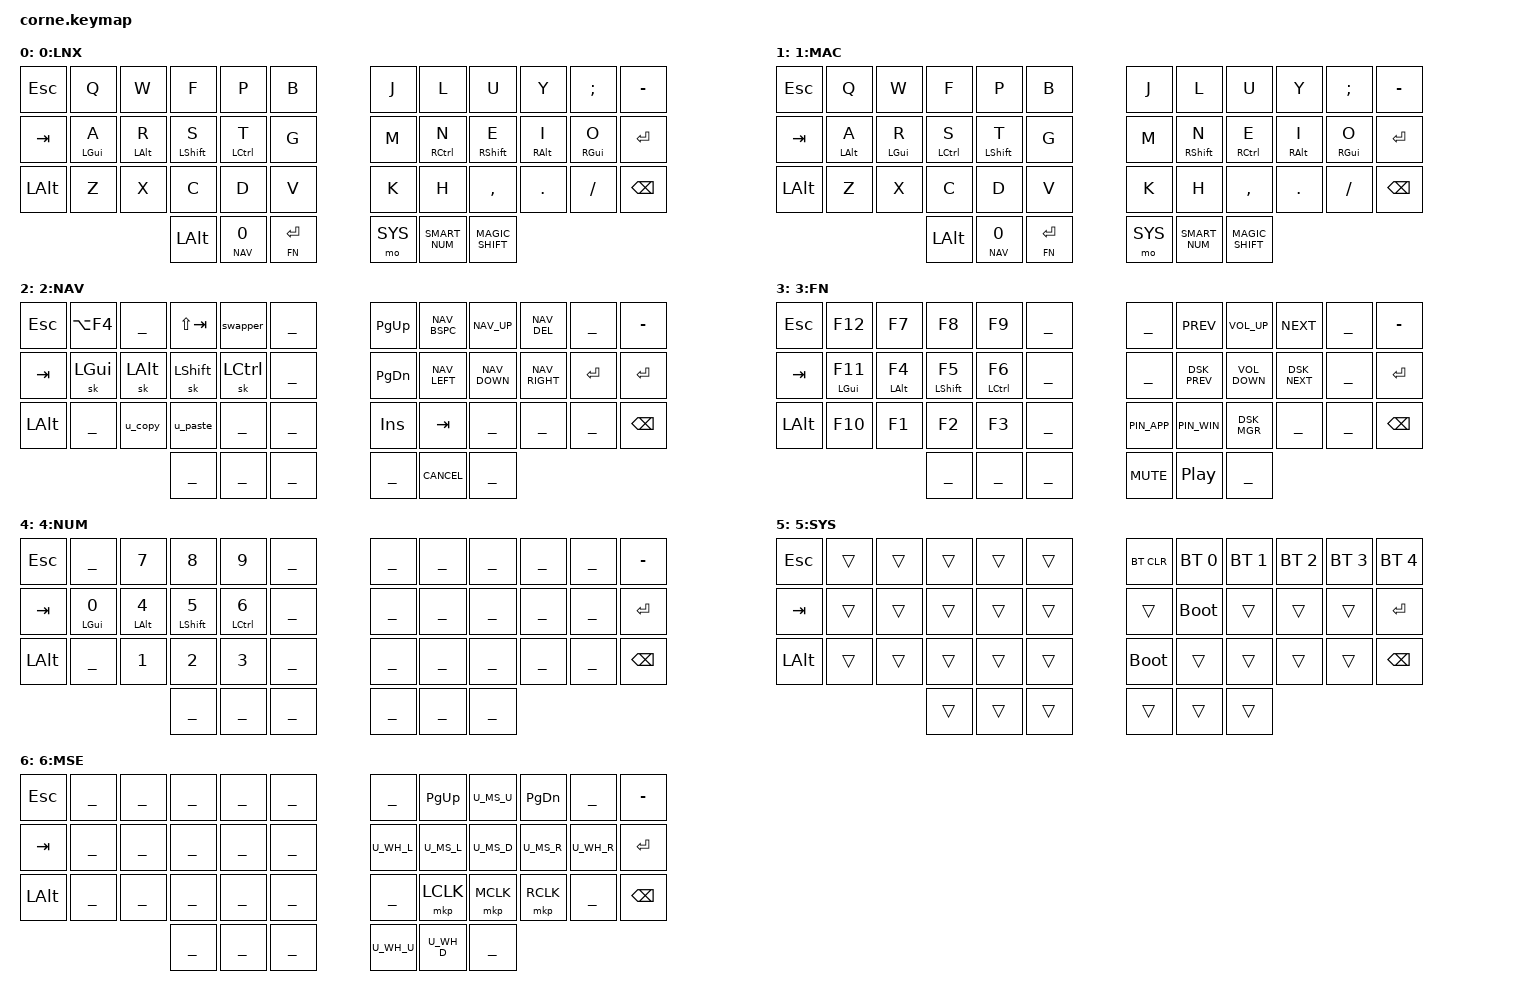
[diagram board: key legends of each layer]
/*
 * Copyright (c) 2020 The ZMK Contributors
 *
 * SPDX-License-Identifier: MIT
 */

#include <behaviors.dtsi>
#include <dt-bindings/zmk/keys.h>
#include <dt-bindings/zmk/bt.h>
#include <dt-bindings/zmk/ext_power.h>
#include <dt-bindings/zmk/outputs.h>

/*
 * Layer indices for Corne
 */
#undef DEF
#undef NAV
#undef FN
#undef NUM
#undef SYS
#undef MOUSE

#define DEF_LNX 0
#define DEF_MAC 1
#define NAV     2
#define FN      3
#define NUM     4
#define SYS     5
#define MOUSE   6

#define DEF DEF_LNX // Override DEF for base.dtsi compatibility

/*
 * Key labels for 42-key Corne
 */
#include "key-labels/42.h"

/*
 * Source the main keymap and helpers
 */
#define CONFIG_WIRELESS
#include "base.dtsi"

/*
 * 42-key Corne layout macro
 */
#undef ZMK_BASE_LAYER
#define ZMK_BASE_LAYER(name, LT, RT, LM, RM, LB, RB, LH, RH) \
    ZMK_LAYER(name, \
        &kp ESC  LT  RT  &kp MINUS \
        &kp TAB  LM  RM  &kp RET \
        &kp LALT LB  RB  &kp BSPC \
              &kp LCTRL LH RH &mo SYS \
    )

/*
 * German Umlaute via vertical combos (US-International layout on OS)
 */
/ {
    combos {
        compatible = "zmk,combos";
        
        // ä: A (LM4) + Z (LB4)
        combo_ae {
            timeout-ms = <50>;
            key-positions = <LM4 LB4>;
            bindings = <&kp RA(Q)>;
            layers = <DEF_LNX DEF_MAC>;
        };
        // ö: O (RM4) + / (RB4)
        combo_oe {
            timeout-ms = <50>;
            key-positions = <RM4 RB4>;
            bindings = <&kp RA(P)>;
            layers = <DEF_LNX DEF_MAC>;
        };
        // ü: U (RT2) + E (RM2)
        combo_ue {
            timeout-ms = <50>;
            key-positions = <RT2 RM2>;
            bindings = <&kp RA(Y)>;
            layers = <DEF_LNX DEF_MAC>;
        };
        // ß: S (LM2) + C (LB2)
        combo_ss {
            timeout-ms = <50>;
            key-positions = <LM2 LB2>;
            bindings = <&kp RA(S)>;
            layers = <DEF_LNX DEF_MAC>;
        };
    };
};

/*
 * OS-aware Unified Macros & Behaviors
 */
/ {
    macros {
        // Universal Copy (Linux): Ctrl+Insert works in terminal AND browser
        copy_lnx: copy_lnx {
            compatible = "zmk,behavior-macro";
            #binding-cells = <0>;
            bindings = <&kp LC(INS)>;
        };
        // Universal Paste (Linux): Shift+Insert works in terminal AND browser
        paste_lnx: paste_lnx {
            compatible = "zmk,behavior-macro";
            #binding-cells = <0>;
            bindings = <&kp LS(INS)>;
        };
    };

    behaviors {
        // Unified Copy Action (Nav layer + C)
        u_copy: u_copy {
            compatible = "zmk,behavior-mod-morph";
            #binding-cells = <0>;
            bindings = <&copy_lnx>, <&kp LG(C)>;
            mods = <(MOD_LGUI)>; // Dummy mapping to separate logic
        };
        // Unified Paste Action (Nav layer + V)
        u_paste: u_paste {
            compatible = "zmk,behavior-mod-morph";
            #binding-cells = <0>;
            bindings = <&paste_lnx>, <&kp LG(V)>;
            mods = <(MOD_LGUI)>;
        };
    };
};

/*
 * Keymap with Mac and Linux layers
 * Aligned HRM strategy: 
 * Middle finger = LCTRL (Universal tool finger for Vim, Zellij, Kill)
 * Index finger = LALT (Linux/Zellij) / LGUI (Mac)
 */
/ {
    keymap {
        compatible = "zmk,keymap";

        // 0: Base Linux (Index finger = Ctrl)
        base_lnx_layer {
            display-name = "0:LNX";
            bindings = <
        &kp ESC   &kp Q       &kp W       &kp F        &kp P        &kp B          &kp J   &kp L        &kp U        &kp Y       &kp SEMI    &kp MINUS
        &kp TAB   &hml LGUI A &hml LALT R &hml LSHFT S &hml LCTRL T &kp G          &kp M   &hmr RCTRL N &hmr RSHFT E &hmr RALT I &hmr RGUI O &kp RET
        &kp LALT  &kp Z       &kp X       &kp C        &kp D        &kp V          &kp K   &kp H        &kp COMMA    &kp DOT     &kp FSLH    &kp BSPC
                                  &kp LALT     &lt_spc NAV 0 &lt FN RET    &mo SYS SMART_NUM MAGIC_SHIFT
            >;
        };

        // 1: Base Mac (Index finger = GUI/Cmd)
        base_mac_layer {
            display-name = "1:MAC";
            bindings = <
        &kp ESC   &kp Q       &kp W       &kp F        &kp P        &kp B          &kp J   &kp L        &kp U        &kp Y       &kp SEMI    &kp MINUS
        &kp TAB   &hml LALT A  &hml LGUI R &hml LCTRL S &hml LSHFT T &kp G          &kp M   &hmr RSHFT N &hmr RCTRL E &hmr RALT I &hmr RGUI O &kp RET
        &kp LALT  &kp Z       &kp X       &kp C        &kp D        &kp V          &kp K   &kp H        &kp COMMA    &kp DOT     &kp FSLH    &kp BSPC
                                  &kp LALT     &lt_spc NAV 0 &lt FN RET    &mo SYS SMART_NUM MAGIC_SHIFT
            >;
        };


        // 2: Nav (Unified Actions)
        nav_layer {
            display-name = "2:NAV";
            bindings = <
&kp ESC   &kp LA(F4)    ___           &kp LS(TAB)   &swapper      ___            &kp PG_UP     NAV_BSPC      NAV_UP        NAV_DEL       ___         &kp MINUS
&kp TAB   &sk LGUI      &sk LALT      &sk LSHFT     &sk LCTRL     ___            &kp PG_DN     NAV_LEFT      NAV_DOWN      NAV_RIGHT     &kp RET     &kp RET
&kp LALT  ___           &u_copy       &u_paste      ___           ___            &kp INS       &kp TAB       ___           ___           ___         &kp BSPC
                                      ___           ___           ___            ___           CANCEL        ___
            >;
        };

        // 3: Fn
        fn_layer {
            display-name = "3:FN";
            bindings = <
&kp ESC   &kp F12       &kp F7        &kp F8        &kp F9        ___            ___           &kp C_PREV    &kp C_VOL_UP  &kp C_NEXT    ___         &kp MINUS
&kp TAB   &hml LGUI F11 &hml LALT F4  &hml LSHFT F5 &hml LCTRL F6 ___            ___           DSK_PREV      VOL_DOWN      DSK_NEXT      ___         &kp RET
&kp LALT  &kp F10       &kp F1        &kp F2        &kp F3        ___            PIN_APP       PIN_WIN       DSK_MGR       ___           ___         &kp BSPC
                                      ___           ___           ___            &kp C_MUTE    &kp C_PP      ___
            >;
        };

        // 4: Num
        num_layer {
            display-name = "4:NUM";
            bindings = <
&kp ESC   ___           &kp N7        &kp N8        &kp N9        ___            ___           ___           ___           ___           ___         &kp MINUS
&kp TAB   &hml LGUI N0  &hml LALT N4  &hml LSHFT N5 &hml LCTRL N6 ___            ___           ___           ___           ___           ___         &kp RET
&kp LALT  ___           &kp N1        &kp N2        &kp N3        ___            ___           ___           ___           ___           ___         &kp BSPC
                                      ___           ___           ___            ___           ___           ___
            >;
        };

        // 5: Sys
        sys_layer {
            display-name = "5:SYS";
            bindings = <
        &kp ESC   &trans        &trans        &trans        &trans        &trans         &bt BT_CLR    &bt BT_SEL 0  &bt BT_SEL 1  &bt BT_SEL 2  &bt BT_SEL 3  &bt BT_SEL 4
        &kp TAB   &trans        &trans        &trans        &trans        &trans         &trans        &bootloader   &trans        &trans        &trans      &kp RET
        &kp LALT  &trans        &trans        &trans        &trans        &trans         &bootloader   &trans        &trans        &trans        &trans      &kp BSPC
                                      &trans        &trans        &trans         &trans        &trans        &trans
            >;
        };


        // 6: Mouse
        mouse_layer {
            display-name = "6:MSE";
            bindings = <
&kp ESC   ___           ___           ___           ___           ___            ___           &kp PG_UP     U_MS_U         &kp PG_DN    ___         &kp MINUS
&kp TAB   ___           ___           ___           ___           ___            U_WH_L        U_MS_L        U_MS_D         U_MS_R       U_WH_R      &kp RET
&kp LALT  ___           ___           ___           ___           ___            ___           &mkp LCLK     &mkp MCLK      &mkp RCLK    ___         &kp BSPC
                                      ___           ___           ___            U_WH_U        U_WH_D        ___
            >;
        };
    };
};
